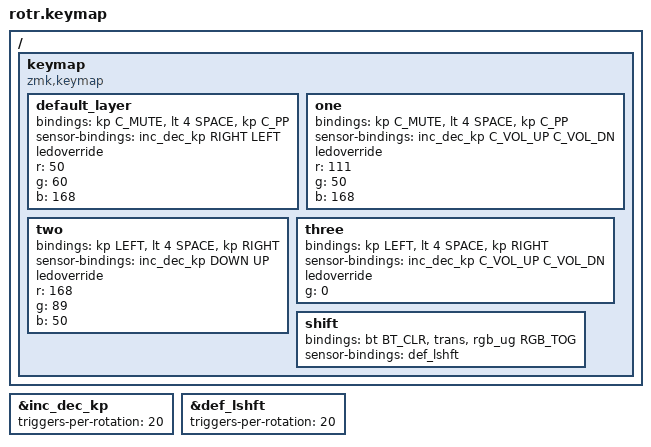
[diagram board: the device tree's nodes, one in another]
#include <behaviors.dtsi>
#include <dt-bindings/zmk/keys.h>
#include <dt-bindings/zmk/rgb.h>
#include <dt-bindings/zmk/bt.h>

&inc_dec_kp {
	triggers-per-rotation = <20>;
};
&def_lshft {
	triggers-per-rotation = <20>;
};

/ {
	keymap {
		compatible = "zmk,keymap";

		default_layer {
			// blue
			bindings = <&kp C_MUTE &lt 4 SPACE &kp C_PP>;
			sensor-bindings = <&inc_dec_kp RIGHT LEFT>;
			ledoverride;
			r = <50>;
			g = <60>;
			b = <168>;
		};
		one {
			// purple
			bindings = <&kp C_MUTE &lt 4 SPACE &kp C_PP>;
			sensor-bindings = <&inc_dec_kp C_VOL_UP C_VOL_DN>;
			ledoverride;
			r = <111>;
			g = <50>;
			b = <168>;
		};
		two {
			// orange
			bindings = <&kp LEFT &lt 4 SPACE &kp RIGHT>;
			sensor-bindings = <&inc_dec_kp DOWN UP>;
			ledoverride;
			r = <168>;
			g = <89>;
			b = <50>;
		};
		three {
			// pink
			bindings = <&kp LEFT &lt 4 SPACE &kp RIGHT>;
			sensor-bindings = <&inc_dec_kp C_VOL_UP C_VOL_DN>;
			ledoverride;
			g = <0>;
		};
		shift {
			bindings = <&bt BT_CLR &trans &rgb_ug RGB_TOG>;
			sensor-bindings = <&def_lshft>;
		};
	};
};
